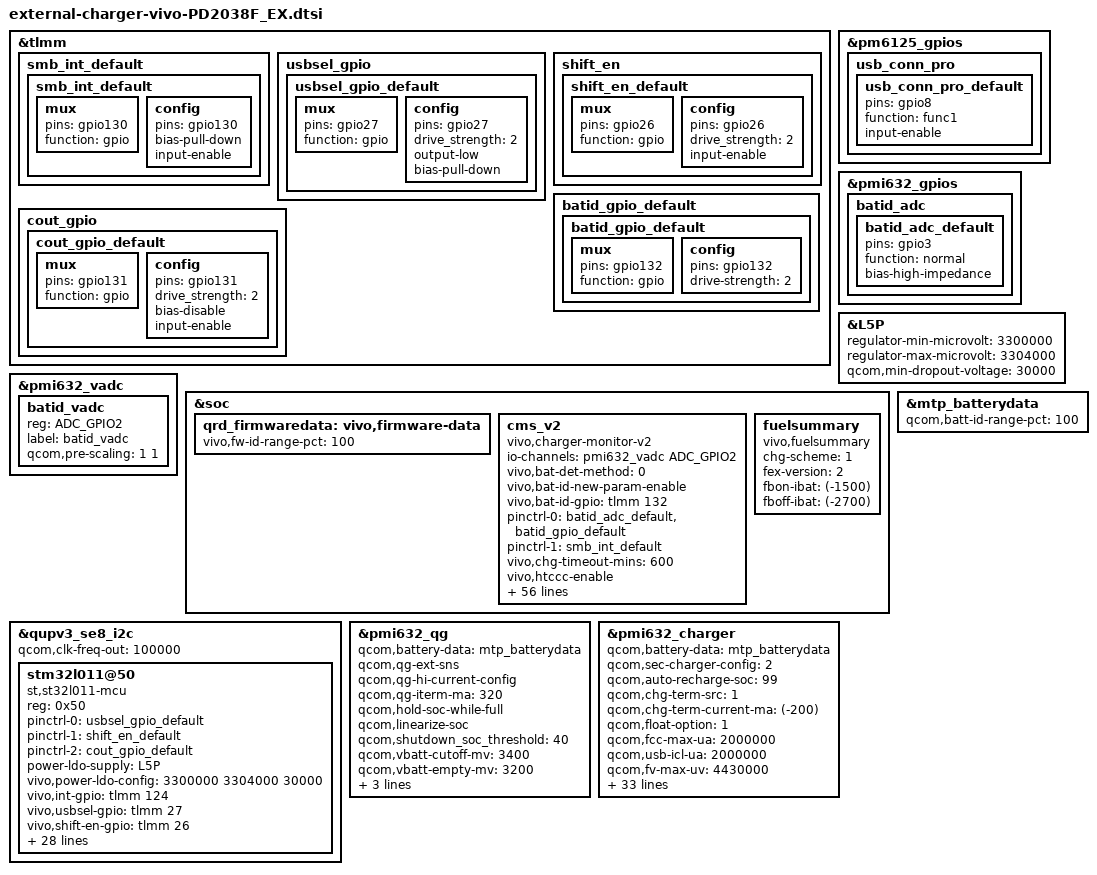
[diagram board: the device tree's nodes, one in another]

&tlmm {
	smb_int_default {
		smb_int_default: smb_int_default {
			mux {
				pins = "gpio130";
				function = "gpio";
			};
			config {
				pins = "gpio130";
				bias-pull-down;
				input-enable;
			};
		};
	};

	usbsel_gpio {
		usbsel_gpio_default: usbsel_gpio_default {
			mux {
				pins = "gpio27";
				function = "gpio";
			};

			config {
				pins = "gpio27";
				drive_strength = <2>;
				output-low;
				bias-pull-down; /* pull down */
			};
		};
	};

	shift_en {
		shift_en_default: shift_en_default {
			mux {
				pins = "gpio26";
				function = "gpio";
			};

			config {
				pins = "gpio26";
				drive_strength = <2>;
				input-enable;
				//bias-pull-down; /* pull down */
			};
		};
	};

	batid_gpio_default {
		batid_gpio_default: batid_gpio_default {
			mux {
				pins = "gpio132";
				function = "gpio";
			};
			config {
				pins = "gpio132";
				drive-strength = <2>;
			};
		};
	};
	cout_gpio {
 		cout_gpio_default: cout_gpio_default {
			mux {
				pins = "gpio131";
				function = "gpio";
			};

		config {
				pins = "gpio131";
				drive_strength = <2>;
				bias-disable;
				input-enable;
			};
		};
 	};
};
&pm6125_gpios {
/*
	shift_en {
		shift_en_default: shift_en_default {
			pins = "gpio26";
			function = "func1";
			input-enable;
		};
	};
*/
	usb_conn_pro {
		usb_conn_pro_default: usb_conn_pro_default {
			pins = "gpio8";
			function = "func1";
			input-enable;
		};
	};
};
&pmi632_gpios {
	batid_adc {
		batid_adc_default: batid_adc_default {
			pins = "gpio3";
			function = "normal";
			bias-high-impedance;
		};
	};
};

#include <dt-bindings/interrupt-controller/irq.h>
&L5P {
	regulator-min-microvolt = <3300000>;
	regulator-max-microvolt = <3304000>;
	qcom,min-dropout-voltage = <30000>;
};


&pmi632_vadc {
	batid_vadc {
		reg = <ADC_GPIO2>;
		label = "batid_vadc";
		qcom,pre-scaling = <1 1>;
	};
};
&soc {
	qrd_firmwaredata: vivo,firmware-data {
		vivo,fw-id-range-pct = <100>;
		#include "mcu-firmware-data-PD2038F_EX.dtsi"
	};
};
&qupv3_se8_i2c {
	status = "ok";
	qcom,clk-freq-out = <100000>;

	stm32l011@50 {
		compatible = "st,st32l011-mcu";
		reg = <0x50>;
		pinctrl-names = "usbsel_gpio_default", "shift_en_default", "cout_gpio_default";
		pinctrl-0 = <&usbsel_gpio_default>;
		pinctrl-1 = <&shift_en_default>;
		pinctrl-2 = <&cout_gpio_default>;

		/*mcu power pin*/
		/*use LDO supply Power directly*/
		power-ldo-supply = <&L5P>;
		vivo,power-ldo-config = <3300000 3304000 30000>;/*min_uV, max_uV, I_load_uA(keep in NPM)*/

		vivo,int-gpio = <&tlmm 124 0>;
		vivo,usbsel-gpio = <&tlmm 27 0>;
		vivo,shift-en-gpio = <&tlmm 26 0>;

		vivo,total-limit-max-ma = <6000>;
		vivo,bigdata-collect-time-limit = <95>;	//seconds
		vivo,direct-charger-enable;

		/*load firmware profile*/
		vivo,firmware-data = <&qrd_firmwaredata>;
		/*FFC charge: */
		vivo,ffc-support;
		vivo,ffc-temperature-range = <150 450>;
		vivo,ffc-cc-to-cv-ibat-thr-rc = <2 3>;
						/*<Tmin Tmax current> */
		vivo,ffc-cc-to-cv-ibat-thr-table = <150 199 3200>,
						   <200 449 4400>;
		vivo,ffc-dchg-cv-mv-rc = <3 2>;
					  /*btb_cv,fg_cv*/
		vivo,ffc-dchg-cv-mv-table = <4450 4430>,/*default*/
					    <4520 4520>,/*single_charging*/
					    <4510 4510>;/*dual_charging*/


		//dual IC : enable_slave_charger
		//vivo,enable-slave-charger;

		//interrupts = <19 8>;// 8 ?
		//pinctrl-names = "default";
		//pinctrl-0 = <&cout_gpio_default>;
		vivo,cout-int-gpio = <&tlmm 131 0>;

		/*enable bat board temp debug layer node*/
		vivo,bat-temp-exist;

		/*BQ25970_SINGLE_DCHG:
		  DCHG_SINGLE_TYPE_22P5W = 0,
		  DCHG_SINGLE_TYPE_33W = 1,
		  DCHG_SINGLE_TYPE_44W = 2,

		  BQ25970_DUAL_DCHG:
		  DCHG_DUAL_TYPE_44W = 3,
		*/
		vivo,dchg-supported-type = <1>;

		/*adapter power derate*/
		vivo,adapter-power-derate-enable;

		/*NTC enable state
		  NTC_NONSUPPORT = 0,
		  NTC_FROM_BQ25970 = 1,
		  NTC_FROM_PMI,
		*/
		vivo,bat-board-temp-enable = <1>;/*default: 0*/
		vivo,usb-conn-temp-enable = <1>;/*default: 0*/
		vivo,bat-conn-temp-enable = <1>;/*default: 1*/
		vivo,master-bat-conn-temp-enable = <0>;/*default: 0*/

		/* bat_board, usb_conn, pcb_conn(master_bat_conn), bat_conn, bq die */
		vivo,dchg-exit-ntc-threshold = <700 650 700 700 1200>;

		//vivo,sbu-cable-id-detect-enable;
		 /* SBUx Cable ID ADC */
 		/*io-channels = <&pm8150l_vadc ADC_AMUX_THM1_PU2>,
 					<&pm8150l_vadc ADC_AMUX_THM3_PU2>;
 		io-channel-names = "sbu1_cable_id_adc",
					"sbu2_cable_id_adc";
		*/
		vivo,cable-r-limit-table-rc = <8 5>;
		vivo,cable-r-limit-table = <(-8888) 381 3000 0 0>,
					   <382 446 2250 0 0>,
					   <447 557 1800 0 0>,
					   <558 8888 0 0 0>,
					   <(-8888) 381 3000 1 0>,
					   <382 446 2250 1 0>,
					   <447 557 1800 1 0>,
					   <558 8888 0 1 0>;
	};
};


&mtp_batterydata {
	qcom,batt-id-range-pct = <100>;
	#include "qg-batterydata-PD2038-4100mah.dtsi"
};

&pmi632_qg {
	qcom,battery-data = <&mtp_batterydata>;
	qcom,qg-ext-sns;
	qcom,qg-hi-current-config;

	qcom,qg-iterm-ma = <320>;
	qcom,hold-soc-while-full;
	qcom,linearize-soc;
	qcom,shutdown_soc_threshold = <40>;

	qcom,vbatt-cutoff-mv = <3400>;
	qcom,vbatt-empty-mv = <3200>;
	qcom,vbatt-empty-cold-mv = <3000>;

	qcom,s3-entry-ibat-ua = <40000>;
	qcom,s3-exit-ibat-ua = <60000>;
	/delete-property/qcom,ibat-use-qg-adc-5a;
};

&pmi632_charger {
	qcom,battery-data = <&mtp_batterydata>;
	qcom,sec-charger-config = <2>;
	qcom,auto-recharge-soc = <99>;
	qcom,chg-term-src = <1>;
	qcom,chg-term-current-ma = <(-200)>;
	qcom,float-option = <1>;

	qcom,fcc-max-ua = <2000000>;
	qcom,usb-icl-ua = <2000000>;
	qcom,fv-max-uv = <4430000>;
	qcom,otg-cl-ua = <1500000>;
	qcom,disable-suspend-on-collapse;

	vivo,direct-charger-enable;
	//vivo,bms-psy-name = "bq_bms";
	qcom,hvdcp-disable;

	/*
	enum SUPPORTED_ADAPTER {
		SUPPORTED_ADAPTER_DEFAULT = 0,
		SUPPORTED_ADAPTER_VIVO_LV_DCHG_5V_4500MA = 1,
		SUPPORTED_ADAPTER_VIVO_HV_DCHG_10V_2250MA = 2,
		SUPPORTED_ADAPTER_QC20__9V_2000MA = 3,
		SUPPORTED_ADAPTER_VIVO_HV_DCHG_10V_4000MA = 4,
		SUPPORTED_ADAPTER_MAX,
	};
	*/
	vivo,supported-adapter = <2>;
	
	vivo,primary-fastchg-max-ua = <6000000>;
	vivo,parallel-fastchg-max-ua = <0>;
	/* vivo,primary-fastchg-max-ua + vivo,parallel-fastchg-max-ua - 1000 */
	vivo,current_spec_min_ma = <3500>;
	/* vivo,primary-fastchg-max-ua + vivo,parallel-fastchg-max-ua + 100 */
	vivo,current_spec_max_ma = <6100>;
	
	/* FFC param */
	vivo,ffc-temperature-range = <150 450>;
	/* ffc iterm and vfloat */
	vivo,ffc-chg-term-current-ma = <(-750)>;
	vivo,ffc-fv-max-uv = <4500000>;
	/* <Tmin  Tmax  current  qg_iterm_delta> */
	vivo,ffc-full-chg-ibat-rc = <3 4>;
	vivo,ffc-full-chg-ibat-table = <150 199 (-892) 412>,
				       <200 349 (-1014) 532>,
				       <350 449 (-1197) 717>;
	/* <VBAT  VBAT_EX  VBAT_TERM> */
	vivo,ffc-full-chg-vbat-table = <4500000 4500000 4480000>;

	
	/*primary board temp & parallel board temp*/
	io-channels = <&pmi632_vadc ADC_USB_IN_V_16>,
		      <&pmi632_vadc ADC_USB_IN_I>,
		      <&pmi632_vadc ADC_CHG_TEMP>,
		      <&pmi632_vadc ADC_DIE_TEMP>,
		      <&pm6125_vadc ADC_AMUX_THM2_PU2>,
		      <&pm6125_vadc ADC_AMUX_THM2_PU2>;
	io-channel-names = "usb_in_voltage",
			   "usb_in_current",
			   "chg_temp",
			   "die_temp",
			   "pri_ntc_temp",
			   "pl_ntc_temp";

	/* pl reuse battery temperature interface */
	//vivo,pl-use-batt-temp-enable;

	/* pl enable gpio config */
	//vivo,pl-enable-gpio = <&pmi632_gpios 2 0x00>;
	//pinctrl-names = "default";
	//pinctrl-0 = <&pl_enable_default>;

	//vivo,usbsel-gpio = <&tlmm 116 0>;
	//vivo,usboe-gpio = <&tlmm 21 0>;

	vivo,soft-term-enable;
	vivo,soft-term-capacity-limit = <100>;
	vivo,soft-term-timer-limit = <54>;//5min

	vivo,tracking_soc_enable;
	vivo,tracking_step_second= <10>;

	/*charge condition force 5v*/
	//vivo,cc-force-5v-soc-limit = <90>;

	/*charge condition force 5v,flashled enable*/
	vivo,cc-force-5v-flashled-enable;

	/*battery temp compensation*/
	//vivo,batt-temp-comp-enable;
	/* usb conn protect function */

	/*vivo add for flashlight blinking when charger plugin*/
	//qcom,headroom-mode = <0>;

	vivo,usb-conn-pro-enable;
	vivo,usb-conn-pro-gpio = <&pm6125_gpios 8 0>;
	pinctrl-names = "default";
	pinctrl-0 = <&usb_conn_pro_default>;
};


&soc {
	cms_v2 {
		compatible = "vivo,charger-monitor-v2";

		//vivo,battery-plugable = <0>;//0:unplugable,1:plugable , default:0

		/* battery ID ADC */
		io-channels = <&pmi632_vadc ADC_GPIO2>;
		io-channel-names = "cms_batt_id";

		vivo,bat-det-method = <0>;  //r:0 , rc:1 , eprom:2, ex-fg:3
		vivo,bat-id-new-param-enable;
		vivo,bat-id-gpio = <&tlmm 132 0x00>;
		pinctrl-names = "default", "smb_int_default";
		pinctrl-0 = <&batid_adc_default &batid_gpio_default>;
		pinctrl-1 = <&smb_int_default>;

		//vivo,no-bat-warning;
		//vivo,no-chg-timeout;
		vivo,chg-timeout-mins = <600>;

		//high temperature charger current control enable
		vivo,htccc-enable;
		vivo,htccc-data = <46 55 4100000 100000>;

		//vivo,fbon-scale-enable;
		vivo,fbon-scale-data = <1 90 100>;

		//vivo,switch-scale-enable;
		vivo,switch-scale-data = <75 60>;

		vivo,calling-scale-enable;
		vivo,calling-scale-data = <100 21>;
		vivo,calling-dchg-disable;

		//vivo,fixed-scale-enable;
		vivo,fixed-scale-data = <120 3800 0>;

		//battery voltage compensate
		vivo,vbat-r-comp = <20>;

		/*data processing : batt-temp*/
		//vivo,dp-batt-temp-enable;
		vivo,dp-batt-temp-data = <100>;

		//ibat scale base on temperature
		vivo,normal-tc-row-col = <8 7>;
			vivo,normal-tc-data = <550 8888 0 0 0 0 0>,
						<450 549 60 0 0 0 0>,
						<200 449 146 4430000 100 0 0>,
						<150 199 150 4200000 120 4430000 80>,
						<100 149 100 0 0 0 0>,
						<50 99 70 4200000 50 0 0>,
						<0 49 50 0 0 0 0>,
						<(-8888) (-1) 0 0 0 0 0>;

			//adjust fastchg base on board temperature and fb off
			vivo,intell-charge-enable;
			//vivo,parallel-temp-enable = <1 1>;//<x y> x:fb-on y:fb-off

			/*Fast charger intell param*/
			//fb-on param
			vivo,primary-fbon-tc-row-col = <7 3>;
			vivo,primary-fbon-tc-data = <461 8888 300>,
						    <446 460 600>,
						    <426 445 2600>,
						    <416 425 3800>,
						    <406 415 4300>,
						    <396 405 4800>,
						    <(-8888) 395 5200>;
			vivo,parallel-fbon-tc-row-col = <1 3>;
			vivo,parallel-fbon-tc-data = <(-8888) 8888 0>;

			//fb-off param
			vivo,primary-fboff-tc-row-col = <7 3>;
			vivo,primary-fboff-tc-data = <431 8888 2400>,
						    <411 430 3200>,
						    <396 410 4000>,
						    <371 395 4200>,
						    <361 370 4700>,
						    <351 360 5200>,
						    <(-8888) 350 6000>;
			vivo,parallel-fboff-tc-row-col = <1 3>;
			vivo,parallel-fboff-tc-data = <(-8888) 8888 0>;

			/*5v Normal charger intell param*/
			//vivo,ex-intell-charge-enable;
			///vivo,ex-parallel-temp-enable = <1 1>;//<x y> x:fb-on y:fb-off
			//fb-on param
			vivo,ex-primary-fbon-tc-row-col = <4 3>;
			vivo,ex-primary-fbon-tc-data = <491 8888 500>,
						    <461 490 800>,
						    <431 460 1500>,
						    <(-8888) 430 2000>;
			vivo,ex-parallel-fbon-tc-row-col = <1 3>;
			vivo,ex-parallel-fbon-tc-data = <(-8888) 8888 0>;

			//fb-off param
			vivo,ex-primary-fboff-tc-row-col = <4 3>;
			vivo,ex-primary-fboff-tc-data = <491 8888 500>,
						    <461 490 800>,
						    <431 460 1500>,
						    <(-8888) 430 2000>;
			vivo,ex-parallel-fboff-tc-row-col = <1 3>;
			vivo,ex-parallel-fboff-tc-data = <(-8888) 8888 0>;

		// Direct charging param
		vivo,direct-charger-enable;
		//vivo,ex-bms-psy-name = "bq_bms";

		// bat_baord, usb_conn, pcb_conn(master_bat_conn), bat_conn
		vivo,dchg-ntc-protect-enable;
		vivo,dchg-ntc-protect-data = <750 800 850 850>;

		vivo,adapter-cooldown-data = <900 850 3400>;	/* Heat_trigger, Heat_recover, fcc */
			/*adapter power derate*/
			vivo,adapter-power-derate-enable;

		/* usb connecter protect param */
		/*
			enum usb_connecter_protect_type {
					USB_PROTECT_NONE = 0,
					USB_CONN_TEMP_HEAT_PROTECT = BIT(0),
					USB_ID_PROTECT = BIT(1),
			};
		*/
		vivo,usb-connecter-protect-enable = <1>;
		vivo,usb-id-protect-data= <1100 1547 500>;	/* 500K, 2M, fcc */
		vivo,usb-conn-heat-protect-data-row-col = <2 4>;
		vivo,usb-conn-heat-protect-data= <260 8888 670 620>,
						<(-8888) 259 570 520>;

		/*
		* max vbus of adapter:11V, max ibus of adapter:3A
		* min voltage of battery for half chg:3500mV,max voltage of battery for half charge:4100mV,
		* 5V2A charge min current threshold: 1000mA,5V2A charge max current threshold:2100mA,
		* flash charge min current threshold:2000mA,flash charge max current threshold:6100mA
		*/
		vivo,charge-param-judge-threshold = <11 3 3500 4100 1000 2100 2000 6100>;
		/* factory mode charging test param */
		vivo,charge-test-param-row-col = <10 3>;
		vivo,charge-test-param-data = <1 0 5500>, /* cable resistance, min value, max value */
									<1 0 3000>, /* master ibus, min ibus, max ibus */
									<0 0 5500>, /* slave ibus, min ibus, max ibus */
									<1 20 40>, /* bat therm ntc, min value, max value */
									<1 20 45>, /* board therm ntc, min value, max value */
									<0 20 50>, /* sub charger ntc, min value, max value */
									<1 20 45>, /* usb con ntc, min value, max value */
									<0 20 45>, /* bat btb master ntc, min value, max value */
									<0 20 50>, /* bat btb sub ntc, min value, max value */
									<1 20 50>; /* bat board ntc, min value, max value */
	};

	fuelsummary {
		compatible = "vivo,fuelsummary";

		/************************************************************
		 *
		 *  0	vivo-fastchg
		 *  1	qcom-dualchg
		 *  2	mtk-dualchg
		 *  3	qcom-normchg
		 *  4	mtk-normchg
		 *
		 ***********************************************************/
		chg-scheme = <1>;
		fex-version = <2>;
		fbon-ibat = <(-1500)>;
		fboff-ibat = <(-2700)>;
	};
};
